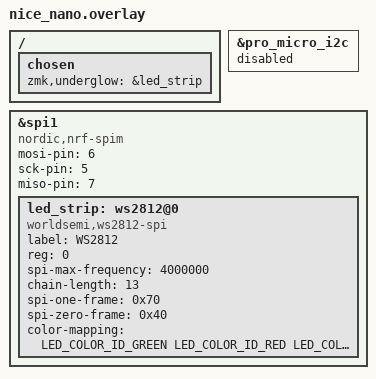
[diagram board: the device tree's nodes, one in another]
#include <dt-bindings/led/led.h>

// nice_view_spi: &spi0 {
// 	compatible = "nordic,nrf-spim";
// 	sck-pin = <20>;
// 	mosi-pin = <22>;
// 	miso-pin = <25>;
// 	cs-gpios = <&gpio0 17 GPIO_ACTIVE_HIGH>;
// };

&pro_micro_i2c {
	status = "disabled";
};

&spi1 {
	compatible = "nordic,nrf-spim";
	/* Cannot be used together with i2c0. */
	status = "okay";
	mosi-pin = <6>;
	// Unused pins, needed for SPI definition, but not used by the ws2812 driver itself.
	sck-pin = <5>;
	miso-pin = <7>;

	led_strip: ws2812@0 {
		compatible = "worldsemi,ws2812-spi";
		label = "WS2812";

		/* SPI */
		reg = <0>; /* ignored, but necessary for SPI bindings */
		spi-max-frequency = <4000000>;

		/* WS2812 */
		chain-length = <13>;
		spi-one-frame = <0x70>;
		spi-zero-frame = <0x40>;

		color-mapping = <LED_COLOR_ID_GREEN LED_COLOR_ID_RED LED_COLOR_ID_BLUE>;
	};
};

/ {
	chosen {
		zmk,underglow = &led_strip;
	};
};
